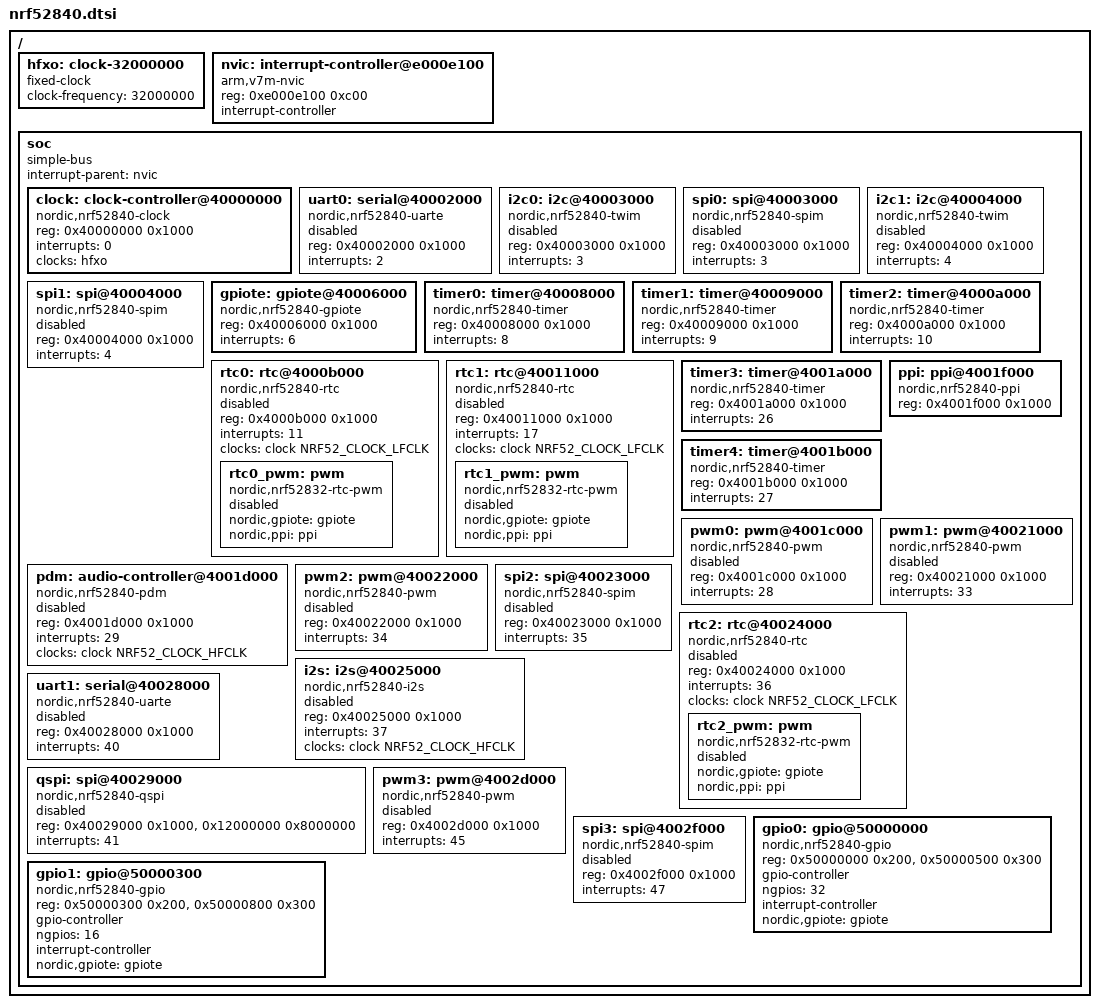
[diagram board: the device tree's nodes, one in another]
// SPDX-FileCopyrightText: 2026 Core Devices LLC
// SPDX-License-Identifier: (GPL-2.0-only OR BSD-2-Clause)

#include <dt-bindings/clock/nordic,nrf52832-clock.h>
#include <dt-bindings/gpio/gpio.h>
#include <dt-bindings/interrupt-controller/irq.h>

/ {
	#address-cells = <1>;
	#size-cells = <1>;

	hfxo: clock-32000000 {
		compatible = "fixed-clock";
		#clock-cells = <0>;
		clock-frequency = <32000000>;
	};

	nvic: interrupt-controller@e000e100 {
		compatible = "arm,v7m-nvic";
		reg = <0xe000e100 0xc00>;
		interrupt-controller;
		#interrupt-cells = <1>;
		#address-cells = <0>;
	};

	soc {
		compatible = "simple-bus";
		#address-cells = <1>;
		#size-cells = <1>;
		interrupt-parent = <&nvic>;
		ranges;

		clock: clock-controller@40000000 {
			compatible = "nordic,nrf52840-clock", "nordic,nrf52832-clock";
			reg = <0x40000000 0x1000>;
			interrupts = <0>;
			#clock-cells = <1>;
			clocks = <&hfxo>;
			clock-names = "hfxo";
		};

		uart0: serial@40002000 {
			compatible = "nordic,nrf52840-uarte", "nordic,nrf52832-uarte";
			reg = <0x40002000 0x1000>;
			interrupts = <2>;
			status = "disabled";
		};

		i2c0: i2c@40003000 {
			compatible = "nordic,nrf52840-twim", "nordic,nrf52832-twim";
			reg = <0x40003000 0x1000>;
			interrupts = <3>;
			#address-cells = <1>;
			#size-cells = <0>;
			status = "disabled";
		};

		spi0: spi@40003000 {
			compatible = "nordic,nrf52840-spim", "nordic,nrf52832-spim";
			reg = <0x40003000 0x1000>;
			interrupts = <3>;
			#address-cells = <1>;
			#size-cells = <0>;
			status = "disabled";
		};

		i2c1: i2c@40004000 {
			compatible = "nordic,nrf52840-twim", "nordic,nrf52832-twim";
			reg = <0x40004000 0x1000>;
			interrupts = <4>;
			#address-cells = <1>;
			#size-cells = <0>;
			status = "disabled";
		};

		spi1: spi@40004000 {
			compatible = "nordic,nrf52840-spim", "nordic,nrf52832-spim";
			reg = <0x40004000 0x1000>;
			interrupts = <4>;
			#address-cells = <1>;
			#size-cells = <0>;
			status = "disabled";
		};

		gpiote: gpiote@40006000 {
			compatible = "nordic,nrf52840-gpiote", "nordic,nrf52832-gpiote";
			reg = <0x40006000 0x1000>;
			interrupts = <6>;
		};

		timer0: timer@40008000 {
			compatible = "nordic,nrf52840-timer", "nordic,nrf52832-timer";
			reg = <0x40008000 0x1000>;
			interrupts = <8>;
		};

		timer1: timer@40009000 {
			compatible = "nordic,nrf52840-timer", "nordic,nrf52832-timer";
			reg = <0x40009000 0x1000>;
			interrupts = <9>;
		};

		timer2: timer@4000a000 {
			compatible = "nordic,nrf52840-timer", "nordic,nrf52832-timer";
			reg = <0x4000a000 0x1000>;
			interrupts = <10>;
		};

		rtc0: rtc@4000b000 {
			compatible = "nordic,nrf52840-rtc", "nordic,nrf52832-rtc";
			reg = <0x4000b000 0x1000>;
			interrupts = <11>;
			clocks = <&clock NRF52_CLOCK_LFCLK>;
			status = "disabled";

			rtc0_pwm: pwm {
				compatible = "nordic,nrf52832-rtc-pwm";
				#pwm-cells = <3>;
				nordic,gpiote = <&gpiote>;
				nordic,ppi = <&ppi>;
				status = "disabled";
			};
		};

		rtc1: rtc@40011000 {
			compatible = "nordic,nrf52840-rtc", "nordic,nrf52832-rtc";
			reg = <0x40011000 0x1000>;
			interrupts = <17>;
			clocks = <&clock NRF52_CLOCK_LFCLK>;
			status = "disabled";

			rtc1_pwm: pwm {
				compatible = "nordic,nrf52832-rtc-pwm";
				#pwm-cells = <3>;
				nordic,gpiote = <&gpiote>;
				nordic,ppi = <&ppi>;
				status = "disabled";
			};
		};

		timer3: timer@4001a000 {
			compatible = "nordic,nrf52840-timer", "nordic,nrf52832-timer";
			reg = <0x4001a000 0x1000>;
			interrupts = <26>;
		};

		timer4: timer@4001b000 {
			compatible = "nordic,nrf52840-timer", "nordic,nrf52832-timer";
			reg = <0x4001b000 0x1000>;
			interrupts = <27>;
		};

		pwm0: pwm@4001c000 {
			compatible = "nordic,nrf52840-pwm", "nordic,nrf52832-pwm";
			reg = <0x4001c000 0x1000>;
			interrupts = <28>;
			#pwm-cells = <3>;
			status = "disabled";
		};

		pdm: audio-controller@4001d000 {
			compatible = "nordic,nrf52840-pdm", "nordic,nrf52832-pdm";
			reg = <0x4001d000 0x1000>;
			interrupts = <29>;
			clocks = <&clock NRF52_CLOCK_HFCLK>;
			#sound-dai-cells = <0>;
			status = "disabled";
		};

		ppi: ppi@4001f000 {
			compatible = "nordic,nrf52840-ppi", "nordic,nrf52832-ppi";
			reg = <0x4001f000 0x1000>;
		};

		pwm1: pwm@40021000 {
			compatible = "nordic,nrf52840-pwm", "nordic,nrf52832-pwm";
			reg = <0x40021000 0x1000>;
			interrupts = <33>;
			#pwm-cells = <3>;
			status = "disabled";
		};

		pwm2: pwm@40022000 {
			compatible = "nordic,nrf52840-pwm", "nordic,nrf52832-pwm";
			reg = <0x40022000 0x1000>;
			interrupts = <34>;
			#pwm-cells = <3>;
			status = "disabled";
		};

		spi2: spi@40023000 {
			compatible = "nordic,nrf52840-spim", "nordic,nrf52832-spim";
			reg = <0x40023000 0x1000>;
			interrupts = <35>;
			#address-cells = <1>;
			#size-cells = <0>;
			status = "disabled";
		};

		rtc2: rtc@40024000 {
			compatible = "nordic,nrf52840-rtc", "nordic,nrf52832-rtc";
			reg = <0x40024000 0x1000>;
			interrupts = <36>;
			clocks = <&clock NRF52_CLOCK_LFCLK>;
			status = "disabled";

			rtc2_pwm: pwm {
				compatible = "nordic,nrf52832-rtc-pwm";
				#pwm-cells = <3>;
				nordic,gpiote = <&gpiote>;
				nordic,ppi = <&ppi>;
				status = "disabled";
			};
		};

		i2s: i2s@40025000 {
			compatible = "nordic,nrf52840-i2s", "nordic,nrf52832-i2s";
			reg = <0x40025000 0x1000>;
			interrupts = <37>;
			clocks = <&clock NRF52_CLOCK_HFCLK>;
			#sound-dai-cells = <0>;
			status = "disabled";
		};

		uart1: serial@40028000 {
			compatible = "nordic,nrf52840-uarte", "nordic,nrf52832-uarte";
			reg = <0x40028000 0x1000>;
			interrupts = <40>;
			status = "disabled";
		};

		qspi: spi@40029000 {
			compatible = "nordic,nrf52840-qspi";
			reg = <0x40029000 0x1000>, <0x12000000 0x8000000>;
			reg-names = "qspi", "qspi_mm";
			interrupts = <41>;
			#address-cells = <1>;
			#size-cells = <0>;
			status = "disabled";
		};

		pwm3: pwm@4002d000 {
			compatible = "nordic,nrf52840-pwm", "nordic,nrf52832-pwm";
			reg = <0x4002d000 0x1000>;
			interrupts = <45>;
			#pwm-cells = <3>;
			status = "disabled";
		};

		spi3: spi@4002f000 {
			compatible = "nordic,nrf52840-spim", "nordic,nrf52832-spim";
			reg = <0x4002f000 0x1000>;
			interrupts = <47>;
			#address-cells = <1>;
			#size-cells = <0>;
			status = "disabled";
		};

		gpio0: gpio@50000000 {
			compatible = "nordic,nrf52840-gpio", "nordic,nrf52832-gpio";
			reg = <0x50000000 0x200>, <0x50000500 0x300>;
			gpio-controller;
			#gpio-cells = <2>;
			ngpios = <32>;
			interrupt-controller;
			#interrupt-cells = <2>;
			nordic,gpiote = <&gpiote>;
		};

		gpio1: gpio@50000300 {
			compatible = "nordic,nrf52840-gpio", "nordic,nrf52832-gpio";
			reg = <0x50000300 0x200>, <0x50000800 0x300>;
			gpio-controller;
			#gpio-cells = <2>;
			ngpios = <16>;
			interrupt-controller;
			#interrupt-cells = <2>;
			nordic,gpiote = <&gpiote>;
		};
	};
};
